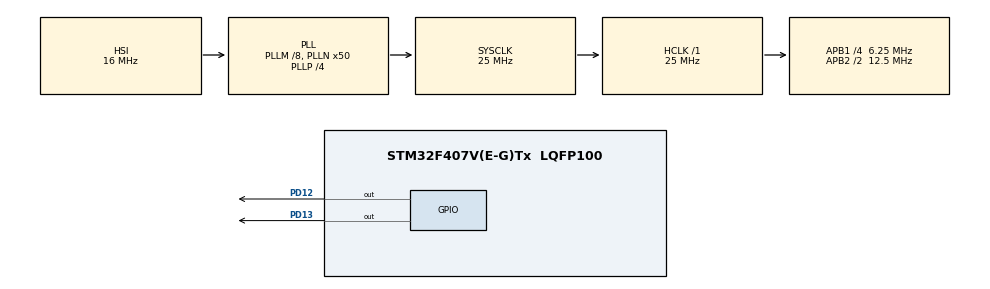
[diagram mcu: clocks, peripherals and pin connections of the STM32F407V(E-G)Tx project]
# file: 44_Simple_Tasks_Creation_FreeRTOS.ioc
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FREERTOS.Tasks01=defaultTask,0,128,StartDefaultTask,Default,NULL,Dynamic,NULL,NULL
Mcu.Family=STM32F4
Mcu.Name=STM32F407V(E-G)Tx
Mcu.Package=LQFP100
NVIC.PriorityGroup=NVIC_PRIORITYGROUP_4
PA13.Mode=Serial_Wire
PA13.Signal=SYS_JTMS-SWDIO
PA14.Mode=Serial_Wire
PA14.Signal=SYS_JTCK-SWCLK
PD12.Signal=GPIO_Output
PD13.Signal=GPIO_Output
ProjectManager.HeapSize=0x200
ProjectManager.StackSize=0x400
ProjectManager.TargetToolchain=STM32CubeIDE
RCC.48MHZClocksFreq_Value=14285714.285714285
RCC.AHBFreq_Value=25000000
RCC.APB1CLKDivider=RCC_HCLK_DIV4
RCC.APB1Freq_Value=6250000
RCC.APB1TimFreq_Value=12500000
RCC.APB2CLKDivider=RCC_HCLK_DIV2
RCC.APB2Freq_Value=12500000
RCC.APB2TimFreq_Value=25000000
RCC.CortexFreq_Value=25000000
RCC.HCLKFreq_Value=25000000
RCC.HSE_VALUE=8000000
RCC.HSI_VALUE=16000000
RCC.PLLM=8
RCC.PLLN=50
RCC.PLLP=RCC_PLLP_DIV4
RCC.PLLQ=7
RCC.SYSCLKFreq_VALUE=25000000
RCC.SYSCLKSource=RCC_SYSCLKSOURCE_PLLCLK
RCC.VCOOutputFreq_Value=100000000
VP_FREERTOS_VS_CMSIS_V1.Mode=CMSIS_V1
board=STM32F407G-DISC1

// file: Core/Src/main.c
#include "main.h"
#include <stdio.h>
#include <stdint.h>

#include "FreeRTOS.h"
#include "task.h"

/* USER CODE BEGIN PV */

TaskHandle_t xTaskHandle1;
TaskHandle_t xTaskHandle2;

/* USER CODE END PV */

void SystemClock_Config(void);
static void MX_GPIO_Init(void);
void StartDefaultTask(void const * argument);

/* USER CODE BEGIN PFP */
void vTask1_handler(void *params);
void vTask2_handler(void *params);

int main(void)
{
	//initialise_monitor_handles();
  /* MCU Configuration--------------------------------------------------------*/

  /* Reset of all peripherals, Initializes the Flash interface and the Systick. */
  HAL_Init();

  /* Configure the system clock */
  SystemClock_Config();

  /* Initialize all configured peripherals */
  MX_GPIO_Init();

  /* Create Task-1 */
    xTaskCreate(vTask1_handler, "Task-1", 256, NULL, 2, &xTaskHandle1);

   /* Create Task-2 */
   xTaskCreate(vTask2_handler, "Task-2", 256, NULL, 2, &xTaskHandle2);

    /* Start Scheduler */
    vTaskStartScheduler();

  /* USER CODE BEGIN WHILE */
  while (1)
  {

  }
  /* USER CODE END 3 */
}

void SystemClock_Config(void)
{
  RCC_OscInitTypeDef RCC_OscInitStruct = {0};
  RCC_ClkInitTypeDef RCC_ClkInitStruct = {0};

  /** Configure the main internal regulator output voltage
  */
  __HAL_RCC_PWR_CLK_ENABLE();
  __HAL_PWR_VOLTAGESCALING_CONFIG(PWR_REGULATOR_VOLTAGE_SCALE1);

  /** Initializes the RCC Oscillators according to the specified parameters
  * in the RCC_OscInitTypeDef structure.
  */
  RCC_OscInitStruct.OscillatorType = RCC_OSCILLATORTYPE_HSI;
  RCC_OscInitStruct.HSIState = RCC_HSI_ON;
  RCC_OscInitStruct.HSICalibrationValue = RCC_HSICALIBRATION_DEFAULT;
  RCC_OscInitStruct.PLL.PLLState = RCC_PLL_ON;
  RCC_OscInitStruct.PLL.PLLSource = RCC_PLLSOURCE_HSI;
  RCC_OscInitStruct.PLL.PLLM = 8;
  RCC_OscInitStruct.PLL.PLLN = 50;
  RCC_OscInitStruct.PLL.PLLP = RCC_PLLP_DIV4;
  RCC_OscInitStruct.PLL.PLLQ = 7;
  if (HAL_RCC_OscConfig(&RCC_OscInitStruct) != HAL_OK)
  {
    Error_Handler();
  }

  /** Initializes the CPU, AHB and APB buses clocks
  */
  RCC_ClkInitStruct.ClockType = RCC_CLOCKTYPE_HCLK|RCC_CLOCKTYPE_SYSCLK
                              |RCC_CLOCKTYPE_PCLK1|RCC_CLOCKTYPE_PCLK2;
  RCC_ClkInitStruct.SYSCLKSource = RCC_SYSCLKSOURCE_PLLCLK;
  RCC_ClkInitStruct.AHBCLKDivider = RCC_SYSCLK_DIV1;
  RCC_ClkInitStruct.APB1CLKDivider = RCC_HCLK_DIV4;
  RCC_ClkInitStruct.APB2CLKDivider = RCC_HCLK_DIV2;

  if (HAL_RCC_ClockConfig(&RCC_ClkInitStruct, FLASH_LATENCY_0) != HAL_OK)
  {
    Error_Handler();
  }
}

static void MX_GPIO_Init(void)
{
  GPIO_InitTypeDef GPIO_InitStruct = {0};

  /* GPIO Ports Clock Enable */
  __HAL_RCC_GPIOD_CLK_ENABLE();
  __HAL_RCC_GPIOA_CLK_ENABLE();

  /*Configure GPIO pin Output Level */
  HAL_GPIO_WritePin(GPIOD, GPIO_PIN_12|GPIO_PIN_13, GPIO_PIN_RESET);

  /*Configure GPIO pins : PD12 PD13 */
  GPIO_InitStruct.Pin = GPIO_PIN_12|GPIO_PIN_13;
  GPIO_InitStruct.Mode = GPIO_MODE_OUTPUT_PP;
  GPIO_InitStruct.Pull = GPIO_NOPULL;
  GPIO_InitStruct.Speed = GPIO_SPEED_FREQ_LOW;
  HAL_GPIO_Init(GPIOD, &GPIO_InitStruct);

}

/* USER CODE BEGIN 4 */
/* Task-1 */
void vTask1_handler(void *params)
{
    while(1)
    {
        /* Toggle Green LED (PD12) */
        HAL_GPIO_TogglePin(GPIOD, GPIO_PIN_12);
        //printf("Task1 Running\n");

        /* Delay 500 ms */
        vTaskDelay(pdMS_TO_TICKS(500));
    }
}

/*============================================================================*/

/* Task-2 */
void vTask2_handler(void *params)
{
    while(1)
    {
        /* Toggle Orange LED (PD13) */
        HAL_GPIO_TogglePin(GPIOD, GPIO_PIN_13);

        //printf("Task2 Running\n");

        /* Delay 1000 ms */
        vTaskDelay(pdMS_TO_TICKS(500));
    }
}

/* USER CODE END 4 */

void Error_Handler(void)
{
  __disable_irq();
  while (1)
  {
  }
}
